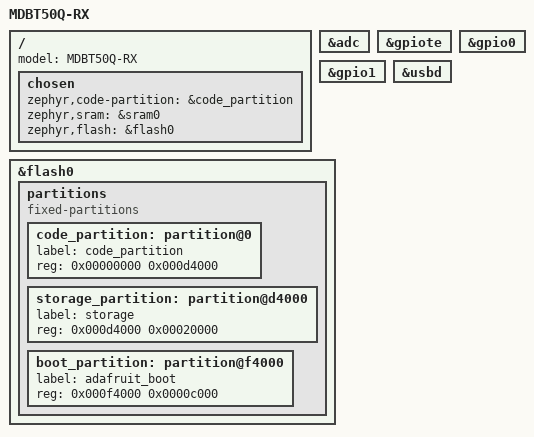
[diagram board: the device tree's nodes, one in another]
/dts-v1/;
#include <nordic/nrf52840_qiaa.dtsi>

/ {
	model = "MDBT50Q-RX";

	chosen {
		zephyr,code-partition = &code_partition;
		zephyr,sram = &sram0;
		zephyr,flash = &flash0;
	};
};

&adc {
	status = "okay";
};

&gpiote {
	status = "okay";
};

&gpio0 {
	status = "okay";
};

&gpio1 {
	status = "okay";
};

&usbd {
	status = "okay";
};

&flash0 {
	partitions {
		compatible = "fixed-partitions";
		#address-cells = <1>;
		#size-cells = <1>;

		code_partition: partition@0 {
			label = "code_partition";
			reg = <0x00000000 0x000d4000>;
		};
		storage_partition: partition@d4000 {
			label = "storage";
			reg = <0x000d4000 0x00020000>;
		};
		boot_partition: partition@f4000 {
			label = "adafruit_boot";
			reg = <0x000f4000 0x0000c000>;
		};
	};
};
